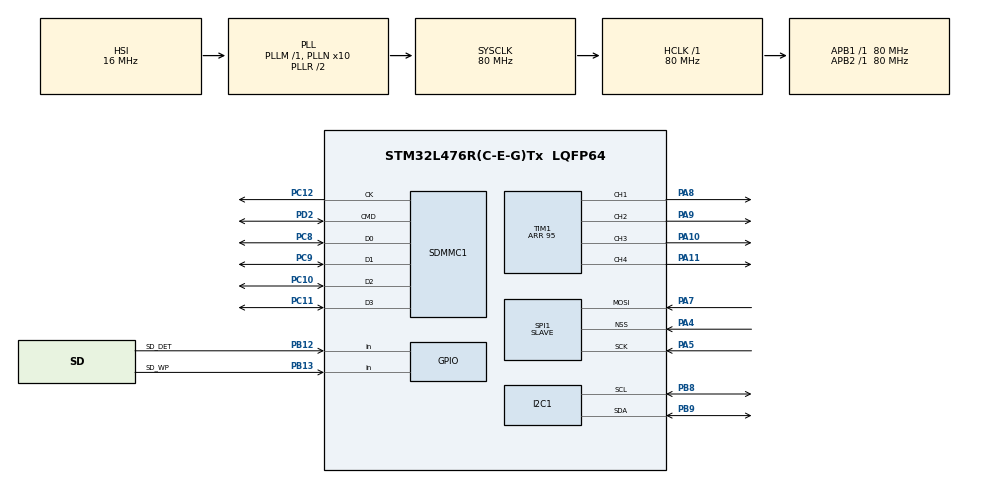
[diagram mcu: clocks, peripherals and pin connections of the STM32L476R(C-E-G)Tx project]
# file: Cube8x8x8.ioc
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Dma.Request0=TIM1_CH2
Dma.Request1=TIM1_CH3
Dma.Request2=TIM1_CH1
Dma.Request3=TIM1_CH4/TRIG/COM
Dma.TIM1_CH1.2.Direction=DMA_MEMORY_TO_PERIPH
Dma.TIM1_CH1.2.Instance=DMA1_Channel2
Dma.TIM1_CH1.2.MemDataAlignment=DMA_MDATAALIGN_BYTE
Dma.TIM1_CH1.2.MemInc=DMA_MINC_ENABLE
Dma.TIM1_CH1.2.Mode=DMA_NORMAL
Dma.TIM1_CH1.2.PeriphDataAlignment=DMA_PDATAALIGN_WORD
Dma.TIM1_CH1.2.PeriphInc=DMA_PINC_DISABLE
Dma.TIM1_CH1.2.Priority=DMA_PRIORITY_HIGH
Dma.TIM1_CH2.0.Direction=DMA_MEMORY_TO_PERIPH
Dma.TIM1_CH2.0.Instance=DMA1_Channel3
Dma.TIM1_CH2.0.MemDataAlignment=DMA_MDATAALIGN_BYTE
Dma.TIM1_CH2.0.MemInc=DMA_MINC_ENABLE
Dma.TIM1_CH2.0.Mode=DMA_NORMAL
Dma.TIM1_CH2.0.PeriphDataAlignment=DMA_PDATAALIGN_WORD
Dma.TIM1_CH2.0.PeriphInc=DMA_PINC_DISABLE
Dma.TIM1_CH2.0.Priority=DMA_PRIORITY_HIGH
Dma.TIM1_CH3.1.Direction=DMA_MEMORY_TO_PERIPH
Dma.TIM1_CH3.1.Instance=DMA1_Channel7
Dma.TIM1_CH3.1.MemDataAlignment=DMA_MDATAALIGN_BYTE
Dma.TIM1_CH3.1.MemInc=DMA_MINC_ENABLE
Dma.TIM1_CH3.1.Mode=DMA_NORMAL
Dma.TIM1_CH3.1.PeriphDataAlignment=DMA_PDATAALIGN_WORD
Dma.TIM1_CH3.1.PeriphInc=DMA_PINC_DISABLE
Dma.TIM1_CH3.1.Priority=DMA_PRIORITY_HIGH
Dma.TIM1_CH4/TRIG/COM.3.Direction=DMA_MEMORY_TO_PERIPH
Dma.TIM1_CH4/TRIG/COM.3.Instance=DMA1_Channel4
Dma.TIM1_CH4/TRIG/COM.3.MemDataAlignment=DMA_MDATAALIGN_BYTE
Dma.TIM1_CH4/TRIG/COM.3.MemInc=DMA_MINC_ENABLE
Dma.TIM1_CH4/TRIG/COM.3.Mode=DMA_NORMAL
Dma.TIM1_CH4/TRIG/COM.3.PeriphDataAlignment=DMA_PDATAALIGN_WORD
Dma.TIM1_CH4/TRIG/COM.3.PeriphInc=DMA_PINC_DISABLE
Dma.TIM1_CH4/TRIG/COM.3.Priority=DMA_PRIORITY_HIGH
FATFS.BSP.number=1
FATFS.USE_DMA_CODE_SD=0
FATFS._MAX_SS=4096
FATFS._USE_FASTSEEK=1
FATFS._USE_FIND=1
FATFS._USE_LFN=1
FATFS._USE_MKFS=0
FATFS0.BSP.STBoard=false
FATFS0.BSP.api=Unknown
FATFS0.BSP.instance=PB12
FATFS0.BSP.ip=GPIO
FATFS0.BSP.mode=Input
FATFS0.BSP.name=Detect_SDIO
FATFS0.BSP.solution=PB12
I2C1.Speed=100
I2C1.Timing=0x00503D58
Mcu.Family=STM32L4
Mcu.Name=STM32L476R(C-E-G)Tx
Mcu.Package=LQFP64
NVIC.DMA1_Channel2_IRQn=true\:0\:0\:false\:false\:true\:false\:true\:true
NVIC.DMA1_Channel3_IRQn=true\:0\:0\:false\:false\:true\:false\:true\:true
NVIC.DMA1_Channel4_IRQn=true\:0\:0\:false\:false\:true\:false\:true\:true
NVIC.DMA1_Channel7_IRQn=true\:0\:0\:false\:false\:true\:false\:true\:true
NVIC.PriorityGroup=NVIC_PRIORITYGROUP_4
NVIC.SPI1_IRQn=true\:0\:0\:false\:false\:true\:true\:true\:true
PA10.GPIO_PuPd=GPIO_NOPULL
PA10.GPIO_Speed=GPIO_SPEED_FREQ_VERY_HIGH
PA10.Signal=S_TIM1_CH3
PA11.GPIO_PuPd=GPIO_NOPULL
PA11.GPIO_Speed=GPIO_SPEED_FREQ_VERY_HIGH
PA11.Signal=S_TIM1_CH4
PA4.Mode=NSS_Signal_Hard_Input
PA4.Signal=SPI1_NSS
PA5.Mode=RX_Only_Simplex_Unidirect_Slave
PA5.Signal=SPI1_SCK
PA7.Mode=RX_Only_Simplex_Unidirect_Slave
PA7.Signal=SPI1_MOSI
PA8.GPIO_PuPd=GPIO_NOPULL
PA8.GPIO_Speed=GPIO_SPEED_FREQ_VERY_HIGH
PA8.Signal=S_TIM1_CH1
PA9.GPIO_PuPd=GPIO_NOPULL
PA9.GPIO_Speed=GPIO_SPEED_FREQ_VERY_HIGH
PA9.Signal=S_TIM1_CH2
PB12.GPIO_Label=SD_DET
PB12.Signal=GPIO_Input
PB13.GPIO_Label=SD_WP
PB13.Signal=GPIO_Input
PB8.Mode=I2C
PB8.Signal=I2C1_SCL
PB9.Mode=I2C
PB9.Signal=I2C1_SDA
PC10.Mode=SD_4_bits_Wide_bus
PC10.Signal=SDMMC1_D2
PC11.Mode=SD_4_bits_Wide_bus
PC11.Signal=SDMMC1_D3
PC12.Mode=SD_4_bits_Wide_bus
PC12.Signal=SDMMC1_CK
PC8.Mode=SD_4_bits_Wide_bus
PC8.Signal=SDMMC1_D0
PC9.Mode=SD_4_bits_Wide_bus
PC9.Signal=SDMMC1_D1
PD2.Mode=SD_4_bits_Wide_bus
PD2.Signal=SDMMC1_CMD
ProjectManager.HeapSize=0x400
ProjectManager.StackSize=0x800
ProjectManager.TargetToolchain=STM32CubeIDE
RCC.ADCFreq_Value=128000000
RCC.AHBFreq_Value=80000000
RCC.APB1Freq_Value=80000000
RCC.APB1TimFreq_Value=80000000
RCC.APB2Freq_Value=80000000
RCC.APB2TimFreq_Value=80000000
RCC.CK48CLockSelection=RCC_USBCLKSOURCE_MSI
RCC.CortexFreq_Value=80000000
RCC.HCLKFreq_Value=80000000
RCC.HSE_VALUE=8000000
RCC.HSI_VALUE=16000000
RCC.I2C1CLockSelection=RCC_I2C1CLKSOURCE_HSI
RCC.LSE_VALUE=32768
RCC.MSI_VALUE=4000000
RCC.PLLN=10
RCC.PLLSAI1N=16
RCC.PLLSourceVirtual=RCC_PLLSOURCE_HSI
RCC.SYSCLKFreq_VALUE=80000000
RCC.SYSCLKSource=RCC_SYSCLKSOURCE_PLLCLK
RCC.USBFreq_Value=4000000
RCC.VCOOutputFreq_Value=160000000
SDMMC1.ClockDiv=16
SH.S_TIM1_CH1.0=TIM1_CH1,PWM Generation1 CH1
SH.S_TIM1_CH2.0=TIM1_CH2,PWM Generation2 CH2
SH.S_TIM1_CH3.0=TIM1_CH3,PWM Generation3 CH3
SH.S_TIM1_CH4.0=TIM1_CH4,PWM Generation4 CH4
SPI1.DataSize=SPI_DATASIZE_8BIT
SPI1.Direction=SPI_DIRECTION_2LINES_RXONLY
SPI1.Mode=SPI_MODE_SLAVE
SPI1.VirtualNSS=VM_NSSHARD
SPI1.VirtualType=VM_SLAVE
TIM1.AutoReloadPreload=TIM_AUTORELOAD_PRELOAD_ENABLE
TIM1.Channel-PWM\ Generation1\ CH1=TIM_CHANNEL_1
TIM1.Channel-PWM\ Generation2\ CH2=TIM_CHANNEL_2
TIM1.Channel-PWM\ Generation3\ CH3=TIM_CHANNEL_3
TIM1.Channel-PWM\ Generation4\ CH4=TIM_CHANNEL_4
TIM1.OC2Preload_PWM=ENABLE
TIM1.Period=95
TIM1.Pulse-PWM\ Generation1\ CH1=0
TIM1.Pulse-PWM\ Generation2\ CH2=0
TIM1.Pulse-PWM\ Generation3\ CH3=0
TIM1.Pulse-PWM\ Generation4\ CH4=0
VP_FATFS_VS_SDIO.Mode=SDIO
VP_TIM1_VS_ClockSourceINT.Mode=Internal
board=custom

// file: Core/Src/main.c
/* USER CODE BEGIN Header */
/**
  ******************************************************************************
  * @file           : main.c
  * @brief          : Main program body
  ******************************************************************************
  * @attention
  *
  * Copyright (c) 2025 STMicroelectronics.
  * All rights reserved.
  *
  * This software is licensed under terms that can be found in the LICENSE file
  * in the root directory of this software component.
  * If no LICENSE file comes with this software, it is provided AS-IS.
  *
  ******************************************************************************
  */
/* USER CODE END Header */
#include "main.h"
#include "fatfs.h"

/* USER CODE BEGIN Includes */
#include "app.h"

/* USER CODE END Includes */

I2C_HandleTypeDef hi2c1;

SD_HandleTypeDef hsd1;

SPI_HandleTypeDef hspi1;

void SystemClock_Config(void);
static void MX_GPIO_Init(void);
static void MX_DMA_Init(void);
static void MX_TIM1_Init(void);
static void MX_SPI1_Init(void);
static void MX_SDMMC1_SD_Init(void);
static void MX_I2C1_Init(void);

int main(void)
{

  /* MCU Configuration--------------------------------------------------------*/

  /* Reset of all peripherals, Initializes the Flash interface and the Systick. */
  HAL_Init();

  /* Configure the system clock */
  SystemClock_Config();

  /* Initialize all configured peripherals */
  MX_GPIO_Init();
  MX_DMA_Init();
  MX_TIM1_Init();
  MX_SPI1_Init();
  MX_SDMMC1_SD_Init();
  MX_I2C1_Init();
  MX_FATFS_Init();
  /* USER CODE BEGIN 2 */
  App_Init();
  /* USER CODE END 2 */

  /* Infinite loop */
  /* USER CODE BEGIN WHILE */
  while (1)
  {
    App_Handler();
    /* USER CODE END WHILE */

  }
}

void SystemClock_Config(void)
{
  RCC_OscInitTypeDef RCC_OscInitStruct = {0};
  RCC_ClkInitTypeDef RCC_ClkInitStruct = {0};

  /** Configure the main internal regulator output voltage
  */
  if (HAL_PWREx_ControlVoltageScaling(PWR_REGULATOR_VOLTAGE_SCALE1) != HAL_OK)
  {
    Error_Handler();
  }

  /** Initializes the RCC Oscillators according to the specified parameters
  * in the RCC_OscInitTypeDef structure.
  */
  RCC_OscInitStruct.OscillatorType = RCC_OSCILLATORTYPE_HSI|RCC_OSCILLATORTYPE_MSI;
  RCC_OscInitStruct.HSIState = RCC_HSI_ON;
  RCC_OscInitStruct.HSICalibrationValue = RCC_HSICALIBRATION_DEFAULT;
  RCC_OscInitStruct.MSIState = RCC_MSI_ON;
  RCC_OscInitStruct.MSICalibrationValue = 0;
  RCC_OscInitStruct.MSIClockRange = RCC_MSIRANGE_6;
  RCC_OscInitStruct.PLL.PLLState = RCC_PLL_ON;
  RCC_OscInitStruct.PLL.PLLSource = RCC_PLLSOURCE_HSI;
  RCC_OscInitStruct.PLL.PLLM = 1;
  RCC_OscInitStruct.PLL.PLLN = 10;
  RCC_OscInitStruct.PLL.PLLP = RCC_PLLP_DIV7;
  RCC_OscInitStruct.PLL.PLLQ = RCC_PLLQ_DIV2;
  RCC_OscInitStruct.PLL.PLLR = RCC_PLLR_DIV2;
  if (HAL_RCC_OscConfig(&RCC_OscInitStruct) != HAL_OK)
  {
    Error_Handler();
  }

  /** Initializes the CPU, AHB and APB buses clocks
  */
  RCC_ClkInitStruct.ClockType = RCC_CLOCKTYPE_HCLK|RCC_CLOCKTYPE_SYSCLK
                              |RCC_CLOCKTYPE_PCLK1|RCC_CLOCKTYPE_PCLK2;
  RCC_ClkInitStruct.SYSCLKSource = RCC_SYSCLKSOURCE_PLLCLK;
  RCC_ClkInitStruct.AHBCLKDivider = RCC_SYSCLK_DIV1;
  RCC_ClkInitStruct.APB1CLKDivider = RCC_HCLK_DIV1;
  RCC_ClkInitStruct.APB2CLKDivider = RCC_HCLK_DIV1;

  if (HAL_RCC_ClockConfig(&RCC_ClkInitStruct, FLASH_LATENCY_4) != HAL_OK)
  {
    Error_Handler();
  }
}

static void MX_I2C1_Init(void)
{

  hi2c1.Instance = I2C1;
  hi2c1.Init.Timing = 0x00503D58;
  hi2c1.Init.OwnAddress1 = 0;
  hi2c1.Init.AddressingMode = I2C_ADDRESSINGMODE_7BIT;
  hi2c1.Init.DualAddressMode = I2C_DUALADDRESS_DISABLE;
  hi2c1.Init.OwnAddress2 = 0;
  hi2c1.Init.OwnAddress2Masks = I2C_OA2_NOMASK;
  hi2c1.Init.GeneralCallMode = I2C_GENERALCALL_DISABLE;
  hi2c1.Init.NoStretchMode = I2C_NOSTRETCH_DISABLE;
  if (HAL_I2C_Init(&hi2c1) != HAL_OK)
  {
    Error_Handler();
  }

  /** Configure Analogue filter
  */
  if (HAL_I2CEx_ConfigAnalogFilter(&hi2c1, I2C_ANALOGFILTER_ENABLE) != HAL_OK)
  {
    Error_Handler();
  }

  /** Configure Digital filter
  */
  if (HAL_I2CEx_ConfigDigitalFilter(&hi2c1, 0) != HAL_OK)
  {
    Error_Handler();
  }

}

static void MX_SDMMC1_SD_Init(void)
{

  hsd1.Instance = SDMMC1;
  hsd1.Init.ClockEdge = SDMMC_CLOCK_EDGE_RISING;
  hsd1.Init.ClockBypass = SDMMC_CLOCK_BYPASS_DISABLE;
  hsd1.Init.ClockPowerSave = SDMMC_CLOCK_POWER_SAVE_DISABLE;
  hsd1.Init.BusWide = SDMMC_BUS_WIDE_4B;
  hsd1.Init.HardwareFlowControl = SDMMC_HARDWARE_FLOW_CONTROL_DISABLE;
  hsd1.Init.ClockDiv = 16;

}

static void MX_SPI1_Init(void)
{

  /* SPI1 parameter configuration*/
  hspi1.Instance = SPI1;
  hspi1.Init.Mode = SPI_MODE_SLAVE;
  hspi1.Init.Direction = SPI_DIRECTION_2LINES_RXONLY;
  hspi1.Init.DataSize = SPI_DATASIZE_8BIT;
  hspi1.Init.CLKPolarity = SPI_POLARITY_LOW;
  hspi1.Init.CLKPhase = SPI_PHASE_1EDGE;
  hspi1.Init.NSS = SPI_NSS_HARD_INPUT;
  hspi1.Init.FirstBit = SPI_FIRSTBIT_MSB;
  hspi1.Init.TIMode = SPI_TIMODE_DISABLE;
  hspi1.Init.CRCCalculation = SPI_CRCCALCULATION_DISABLE;
  hspi1.Init.CRCPolynomial = 7;
  hspi1.Init.CRCLength = SPI_CRC_LENGTH_DATASIZE;
  hspi1.Init.NSSPMode = SPI_NSS_PULSE_DISABLE;
  if (HAL_SPI_Init(&hspi1) != HAL_OK)
  {
    Error_Handler();
  }

}

static void MX_TIM1_Init(void)
{

  LL_TIM_InitTypeDef TIM_InitStruct = {0};
  LL_TIM_OC_InitTypeDef TIM_OC_InitStruct = {0};
  LL_TIM_BDTR_InitTypeDef TIM_BDTRInitStruct = {0};

  LL_GPIO_InitTypeDef GPIO_InitStruct = {0};

  /* Peripheral clock enable */
  LL_APB2_GRP1_EnableClock(LL_APB2_GRP1_PERIPH_TIM1);

  /* TIM1 DMA Init */

  /* TIM1_CH2 Init */
  LL_DMA_SetPeriphRequest(DMA1, LL_DMA_CHANNEL_3, LL_DMA_REQUEST_7);

  LL_DMA_SetDataTransferDirection(DMA1, LL_DMA_CHANNEL_3, LL_DMA_DIRECTION_MEMORY_TO_PERIPH);

  LL_DMA_SetChannelPriorityLevel(DMA1, LL_DMA_CHANNEL_3, LL_DMA_PRIORITY_HIGH);

  LL_DMA_SetMode(DMA1, LL_DMA_CHANNEL_3, LL_DMA_MODE_NORMAL);

  LL_DMA_SetPeriphIncMode(DMA1, LL_DMA_CHANNEL_3, LL_DMA_PERIPH_NOINCREMENT);

  LL_DMA_SetMemoryIncMode(DMA1, LL_DMA_CHANNEL_3, LL_DMA_MEMORY_INCREMENT);

  LL_DMA_SetPeriphSize(DMA1, LL_DMA_CHANNEL_3, LL_DMA_PDATAALIGN_WORD);

  LL_DMA_SetMemorySize(DMA1, LL_DMA_CHANNEL_3, LL_DMA_MDATAALIGN_BYTE);

  /* TIM1_CH3 Init */
  LL_DMA_SetPeriphRequest(DMA1, LL_DMA_CHANNEL_7, LL_DMA_REQUEST_7);

  LL_DMA_SetDataTransferDirection(DMA1, LL_DMA_CHANNEL_7, LL_DMA_DIRECTION_MEMORY_TO_PERIPH);

  LL_DMA_SetChannelPriorityLevel(DMA1, LL_DMA_CHANNEL_7, LL_DMA_PRIORITY_HIGH);

  LL_DMA_SetMode(DMA1, LL_DMA_CHANNEL_7, LL_DMA_MODE_NORMAL);

  LL_DMA_SetPeriphIncMode(DMA1, LL_DMA_CHANNEL_7, LL_DMA_PERIPH_NOINCREMENT);

  LL_DMA_SetMemoryIncMode(DMA1, LL_DMA_CHANNEL_7, LL_DMA_MEMORY_INCREMENT);

  LL_DMA_SetPeriphSize(DMA1, LL_DMA_CHANNEL_7, LL_DMA_PDATAALIGN_WORD);

  LL_DMA_SetMemorySize(DMA1, LL_DMA_CHANNEL_7, LL_DMA_MDATAALIGN_BYTE);

  /* TIM1_CH1 Init */
  LL_DMA_SetPeriphRequest(DMA1, LL_DMA_CHANNEL_2, LL_DMA_REQUEST_7);

  LL_DMA_SetDataTransferDirection(DMA1, LL_DMA_CHANNEL_2, LL_DMA_DIRECTION_MEMORY_TO_PERIPH);

  LL_DMA_SetChannelPriorityLevel(DMA1, LL_DMA_CHANNEL_2, LL_DMA_PRIORITY_HIGH);

  LL_DMA_SetMode(DMA1, LL_DMA_CHANNEL_2, LL_DMA_MODE_NORMAL);

  LL_DMA_SetPeriphIncMode(DMA1, LL_DMA_CHANNEL_2, LL_DMA_PERIPH_NOINCREMENT);

  LL_DMA_SetMemoryIncMode(DMA1, LL_DMA_CHANNEL_2, LL_DMA_MEMORY_INCREMENT);

  LL_DMA_SetPeriphSize(DMA1, LL_DMA_CHANNEL_2, LL_DMA_PDATAALIGN_WORD);

  LL_DMA_SetMemorySize(DMA1, LL_DMA_CHANNEL_2, LL_DMA_MDATAALIGN_BYTE);

  /* TIM1_CH4_TRIG_COM Init */
  LL_DMA_SetPeriphRequest(DMA1, LL_DMA_CHANNEL_4, LL_DMA_REQUEST_7);

  LL_DMA_SetDataTransferDirection(DMA1, LL_DMA_CHANNEL_4, LL_DMA_DIRECTION_MEMORY_TO_PERIPH);

  LL_DMA_SetChannelPriorityLevel(DMA1, LL_DMA_CHANNEL_4, LL_DMA_PRIORITY_HIGH);

  LL_DMA_SetMode(DMA1, LL_DMA_CHANNEL_4, LL_DMA_MODE_NORMAL);

  LL_DMA_SetPeriphIncMode(DMA1, LL_DMA_CHANNEL_4, LL_DMA_PERIPH_NOINCREMENT);

  LL_DMA_SetMemoryIncMode(DMA1, LL_DMA_CHANNEL_4, LL_DMA_MEMORY_INCREMENT);

  LL_DMA_SetPeriphSize(DMA1, LL_DMA_CHANNEL_4, LL_DMA_PDATAALIGN_WORD);

  LL_DMA_SetMemorySize(DMA1, LL_DMA_CHANNEL_4, LL_DMA_MDATAALIGN_BYTE);

  TIM_InitStruct.Prescaler = 0;
  TIM_InitStruct.CounterMode = LL_TIM_COUNTERMODE_UP;
  TIM_InitStruct.Autoreload = 95;
  TIM_InitStruct.ClockDivision = LL_TIM_CLOCKDIVISION_DIV1;
  TIM_InitStruct.RepetitionCounter = 0;
  LL_TIM_Init(TIM1, &TIM_InitStruct);
  LL_TIM_EnableARRPreload(TIM1);
  LL_TIM_SetClockSource(TIM1, LL_TIM_CLOCKSOURCE_INTERNAL);
  LL_TIM_OC_EnablePreload(TIM1, LL_TIM_CHANNEL_CH1);
  TIM_OC_InitStruct.OCMode = LL_TIM_OCMODE_PWM1;
  TIM_OC_InitStruct.OCState = LL_TIM_OCSTATE_DISABLE;
  TIM_OC_InitStruct.OCNState = LL_TIM_OCSTATE_DISABLE;
  TIM_OC_InitStruct.CompareValue = 0;
  TIM_OC_InitStruct.OCPolarity = LL_TIM_OCPOLARITY_HIGH;
  TIM_OC_InitStruct.OCNPolarity = LL_TIM_OCPOLARITY_HIGH;
  TIM_OC_InitStruct.OCIdleState = LL_TIM_OCIDLESTATE_LOW;
  TIM_OC_InitStruct.OCNIdleState = LL_TIM_OCIDLESTATE_LOW;
  LL_TIM_OC_Init(TIM1, LL_TIM_CHANNEL_CH1, &TIM_OC_InitStruct);
  LL_TIM_OC_DisableFast(TIM1, LL_TIM_CHANNEL_CH1);
  LL_TIM_OC_EnablePreload(TIM1, LL_TIM_CHANNEL_CH2);
  LL_TIM_OC_Init(TIM1, LL_TIM_CHANNEL_CH2, &TIM_OC_InitStruct);
  LL_TIM_OC_DisableFast(TIM1, LL_TIM_CHANNEL_CH2);
  LL_TIM_OC_EnablePreload(TIM1, LL_TIM_CHANNEL_CH3);
  LL_TIM_OC_Init(TIM1, LL_TIM_CHANNEL_CH3, &TIM_OC_InitStruct);
  LL_TIM_OC_DisableFast(TIM1, LL_TIM_CHANNEL_CH3);
  LL_TIM_OC_EnablePreload(TIM1, LL_TIM_CHANNEL_CH4);
  LL_TIM_OC_Init(TIM1, LL_TIM_CHANNEL_CH4, &TIM_OC_InitStruct);
  LL_TIM_OC_DisableFast(TIM1, LL_TIM_CHANNEL_CH4);
  LL_TIM_SetOCRefClearInputSource(TIM1, LL_TIM_OCREF_CLR_INT_NC);
  LL_TIM_DisableExternalClock(TIM1);
  LL_TIM_ConfigETR(TIM1, LL_TIM_ETR_POLARITY_NONINVERTED, LL_TIM_ETR_PRESCALER_DIV1, LL_TIM_ETR_FILTER_FDIV1);
  LL_TIM_SetTriggerOutput(TIM1, LL_TIM_TRGO_RESET);
  LL_TIM_SetTriggerOutput2(TIM1, LL_TIM_TRGO2_RESET);
  LL_TIM_DisableMasterSlaveMode(TIM1);
  TIM_BDTRInitStruct.OSSRState = LL_TIM_OSSR_DISABLE;
  TIM_BDTRInitStruct.OSSIState = LL_TIM_OSSI_DISABLE;
  TIM_BDTRInitStruct.LockLevel = LL_TIM_LOCKLEVEL_OFF;
  TIM_BDTRInitStruct.DeadTime = 0;
  TIM_BDTRInitStruct.BreakState = LL_TIM_BREAK_DISABLE;
  TIM_BDTRInitStruct.BreakPolarity = LL_TIM_BREAK_POLARITY_HIGH;
  TIM_BDTRInitStruct.BreakFilter = LL_TIM_BREAK_FILTER_FDIV1;
  TIM_BDTRInitStruct.Break2State = LL_TIM_BREAK2_DISABLE;
  TIM_BDTRInitStruct.Break2Polarity = LL_TIM_BREAK2_POLARITY_HIGH;
  TIM_BDTRInitStruct.Break2Filter = LL_TIM_BREAK2_FILTER_FDIV1;
  TIM_BDTRInitStruct.AutomaticOutput = LL_TIM_AUTOMATICOUTPUT_DISABLE;
  LL_TIM_BDTR_Init(TIM1, &TIM_BDTRInitStruct);
  LL_AHB2_GRP1_EnableClock(LL_AHB2_GRP1_PERIPH_GPIOA);
  /**TIM1 GPIO Configuration
  PA8   ------> TIM1_CH1
  PA9   ------> TIM1_CH2
  PA10   ------> TIM1_CH3
  PA11   ------> TIM1_CH4
  */
  GPIO_InitStruct.Pin = LL_GPIO_PIN_8|LL_GPIO_PIN_9|LL_GPIO_PIN_10|LL_GPIO_PIN_11;
  GPIO_InitStruct.Mode = LL_GPIO_MODE_ALTERNATE;
  GPIO_InitStruct.Speed = LL_GPIO_SPEED_FREQ_VERY_HIGH;
  GPIO_InitStruct.OutputType = LL_GPIO_OUTPUT_PUSHPULL;
  GPIO_InitStruct.Pull = LL_GPIO_PULL_NO;
  GPIO_InitStruct.Alternate = LL_GPIO_AF_1;
  LL_GPIO_Init(GPIOA, &GPIO_InitStruct);

}

static void MX_DMA_Init(void)
{

  /* Init with LL driver */
  /* DMA controller clock enable */
  LL_AHB1_GRP1_EnableClock(LL_AHB1_GRP1_PERIPH_DMA1);

  /* DMA interrupt init */
  /* DMA1_Channel2_IRQn interrupt configuration */
  NVIC_SetPriority(DMA1_Channel2_IRQn, NVIC_EncodePriority(NVIC_GetPriorityGrouping(),0, 0));
  NVIC_EnableIRQ(DMA1_Channel2_IRQn);
  /* DMA1_Channel3_IRQn interrupt configuration */
  NVIC_SetPriority(DMA1_Channel3_IRQn, NVIC_EncodePriority(NVIC_GetPriorityGrouping(),0, 0));
  NVIC_EnableIRQ(DMA1_Channel3_IRQn);
  /* DMA1_Channel4_IRQn interrupt configuration */
  NVIC_SetPriority(DMA1_Channel4_IRQn, NVIC_EncodePriority(NVIC_GetPriorityGrouping(),0, 0));
  NVIC_EnableIRQ(DMA1_Channel4_IRQn);
  /* DMA1_Channel7_IRQn interrupt configuration */
  NVIC_SetPriority(DMA1_Channel7_IRQn, NVIC_EncodePriority(NVIC_GetPriorityGrouping(),0, 0));
  NVIC_EnableIRQ(DMA1_Channel7_IRQn);

}

static void MX_GPIO_Init(void)
{
  GPIO_InitTypeDef GPIO_InitStruct = {0};

  /* GPIO Ports Clock Enable */
  __HAL_RCC_GPIOA_CLK_ENABLE();
  __HAL_RCC_GPIOB_CLK_ENABLE();
  __HAL_RCC_GPIOC_CLK_ENABLE();
  __HAL_RCC_GPIOD_CLK_ENABLE();

  /*Configure GPIO pins : SD_DET_Pin SD_WP_Pin */
  GPIO_InitStruct.Pin = SD_DET_Pin|SD_WP_Pin;
  GPIO_InitStruct.Mode = GPIO_MODE_INPUT;
  GPIO_InitStruct.Pull = GPIO_NOPULL;
  HAL_GPIO_Init(GPIOB, &GPIO_InitStruct);

}

void Error_Handler(void)
{
  __disable_irq();
  while (1)
  {
  }
}
